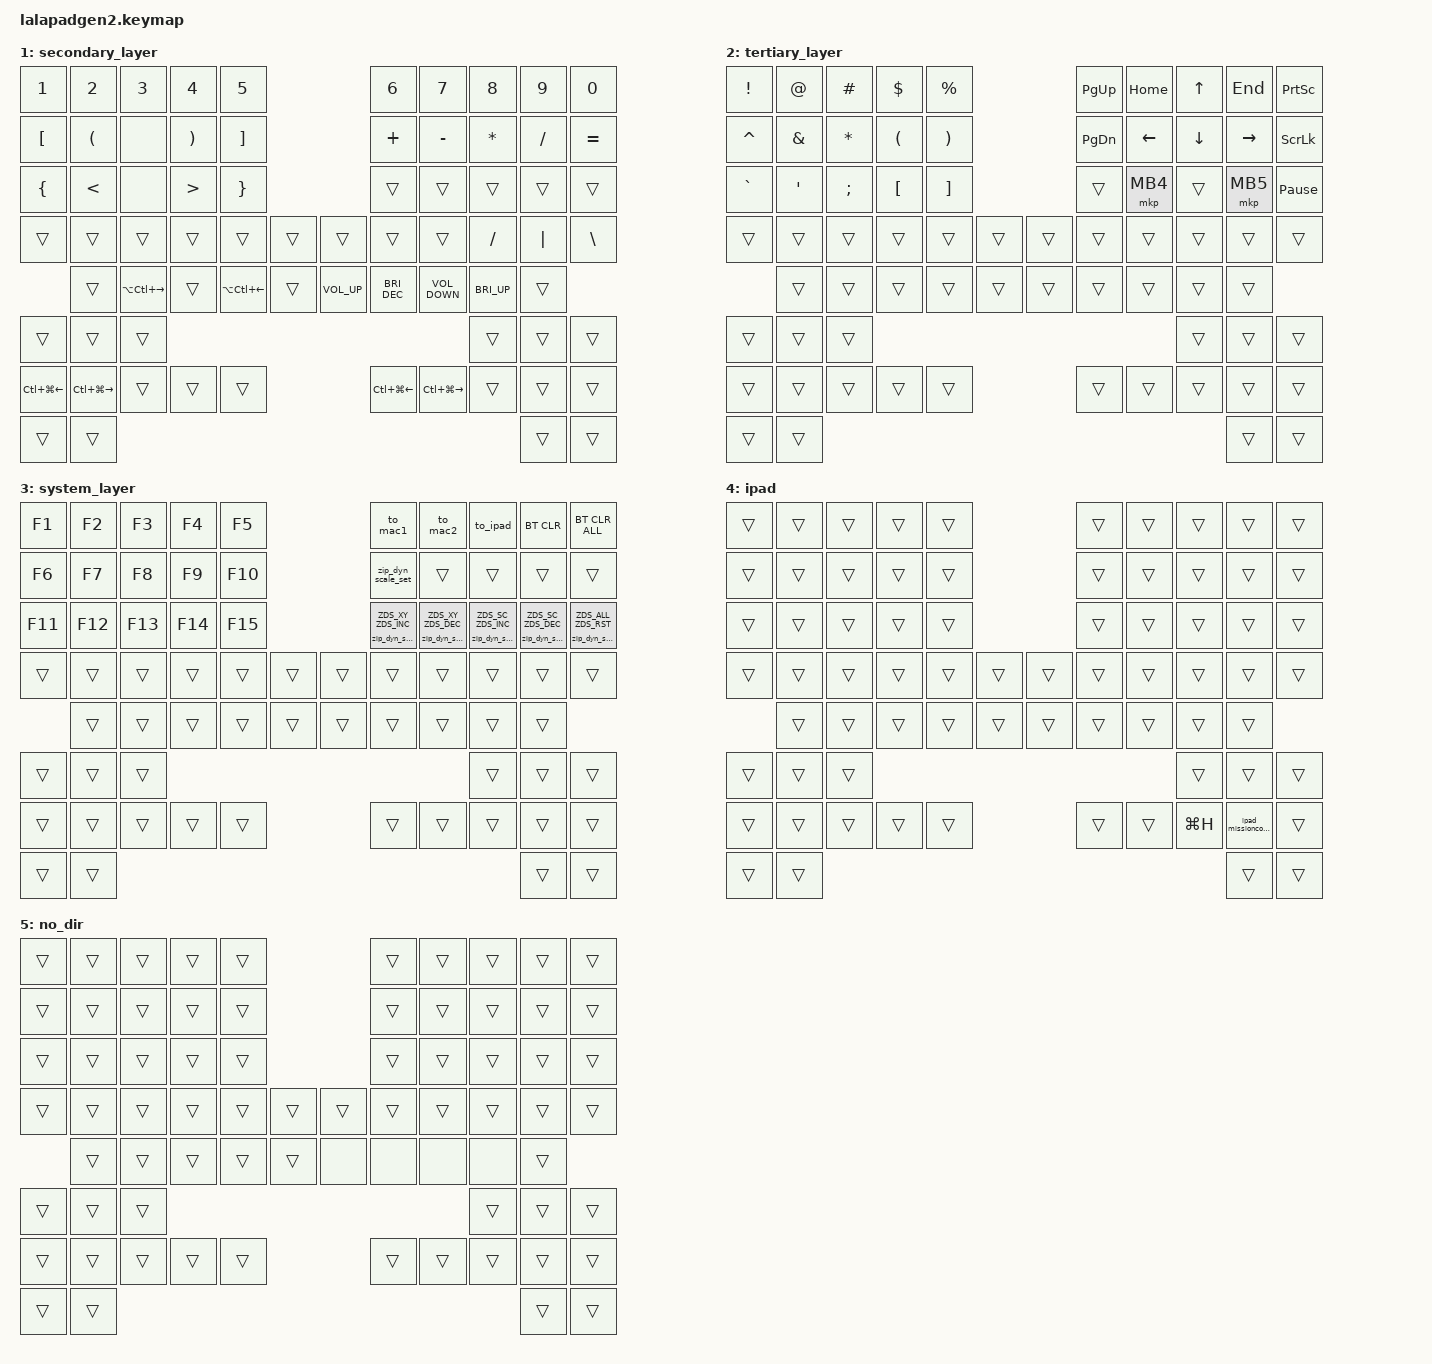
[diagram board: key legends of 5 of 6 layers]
#include <input/processors.dtsi>
#include <dt-bindings/zmk/zip_dynamic_scale.h>
#include <behaviors.dtsi>
#include <dt-bindings/zmk/bt.h>
#include <dt-bindings/zmk/keys.h>
#include <dt-bindings/zmk/pointing.h>

#define DEFAULT_LAYER   0
#define SECONDARY_LAYER 1
#define TERTIARY_LAYER  2
#define SYSTEM_LAYER    3

&mt {
    quick-tap-ms = <250>;
    flavor = "balanced";
};

&lt { quick-tap-ms = <200>; };

/ {
    behaviors {
        dirtap: dirtap {
            compatible = "zmk,behavior-hold-tap";
            label = "DIRTAP";
            #binding-cells = <2>;
            flavor = "tap-unless-interrupted";
            tapping-term-ms = <300>;
            bindings = <&none>, <&kp>;
        };

        zip_dyn_scale: zip_dyn_scale {
            compatible = "zmk,behavior-zip-dynamic-scale";
            #binding-cells = <2>;
        };

        zip_dyn_scale_set: zip_dyn_scale_set {
            compatible = "zmk,behavior-zip-dynamic-scale-set";
            #binding-cells = <2>;
        };

        mt2: mod_tap2 {
            compatible = "zmk,behavior-hold-tap";
            #binding-cells = <2>;
            flavor = "balanced";
            tapping-term-ms = <250>;
            quick-tap-ms = <200>;
            require-prior-idle-ms = <125>;
            bindings = <&kp>, <&kp>;
        };

        tap_dance_layer_1and2: tap_dance_layer_1and2 {
            compatible = "zmk,behavior-tap-dance";
            label = "td_mo12";
            #binding-cells = <0>;
            bindings = <&mo 2>, <&mo 3>;
        };

        mt3: mt3 {
            compatible = "zmk,behavior-hold-tap";
            #binding-cells = <2>;
            flavor = "balanced";
            tapping-term-ms = <250>;
            quick-tap-ms = <200>;
            require-prior-idle-ms = <125>;
            bindings = <&mkp>, <&kp>;

            label = "MT3";
        };

        // 音声入力（VoiceInk）用。タップ=かな／長押し=右⌘（AI なしで録音）／
        // タップしてすぐ押し続ける=右⌥（AI で整えて録音）
        td_voice: td_voice {
            compatible = "zmk,behavior-tap-dance";
            label = "TD_VOICE";
            #binding-cells = <0>;
            tapping-term-ms = <200>;
            bindings = <&mt RIGHT_COMMAND LANGUAGE_1>, <&kp RIGHT_ALT>;
        };

        tap_dance: tap_dance {
            compatible = "zmk,behavior-tap-dance";
            label = "TAP_DANCE";
            #binding-cells = <0>;
            bindings = <&kp T>, <&kp LG(LS(T))>, <&none>;
        };
    };

    combos {
        compatible = "zmk,combos";

        screenshot {
            bindings = <&kp LG(LS(LC(NUMBER_4)))>;
            key-positions = <30 32>;
        };

        screen_capture {
            bindings = <&kp LG(LS(N5))>;
            key-positions = <30 31>;
        };

        task_manager {
            bindings = <&kp LG(LA(ESCAPE))>;
            key-positions = <30 10>;
        };

        lock {
            bindings = <&kp LC(LG(Q))>;
            key-positions = <30 0>;
        };

        escape {
            bindings = <&kp ESCAPE>;
            key-positions = <0 1>;
        };

        copy_pass {
            bindings = <&kp LA(LG(C))>;
            key-positions = <31 32>;
        };
    };

    macros {
        word: word {
            compatible = "zmk,behavior-macro";
            #binding-cells = <0>;
            bindings = <&macro_press &mo 5>, <&macro_tap &kp LANGUAGE_2 &kp LS(T) &kp K &kp Y &kp T &kp M &kp N &kp N5 &kp NUMBER_2 &kp NUMBER_4 &kp N8 &kp ENTER>, <&macro_pause_for_release>, <&macro_release &mo 5>;
            label = "WORD";
        };

        ipad_missioncontroll: ipad_missioncontroll {
            compatible = "zmk,behavior-macro";
            #binding-cells = <0>;
            bindings =
                <&macro_press>,
                <&kp GLOBE>,
                <&macro_tap>,
                <&kp UP>,
                <&macro_release>,
                <&kp GLOBE>;

            label = "IPAD_MISSIONCONTROLL";
        };

        to_mac1: to_mac1 {
            compatible = "zmk,behavior-macro";
            #binding-cells = <0>;
            bindings = <&bt BT_SEL 0 &to 0>;
            label = "TO_MAC1";
        };

        to_mac2: to_mac2 {
            compatible = "zmk,behavior-macro";
            #binding-cells = <0>;
            bindings = <&bt BT_SEL 1 &to 0>;
            label = "TO_MAC2";
        };

        to_ipad: to_ipad {
            compatible = "zmk,behavior-macro";
            #binding-cells = <0>;
            bindings = <&bt BT_SEL 2 &tog 4>;
            label = "TO_IPAD";
        };
    };

    keymap {
        compatible = "zmk,keymap";

        DEFAULT_LAYER {
            display-name = "Default";
            bindings = <
&mt2 SQT Q            &mt2 DOUBLE_QUOTES W  &mt2 GRAVE E          &kp R                         &mt2 TILDE T                                         &kp Y               &kp U            &kp I                 &kp O               &mt2 PERCENT P
&mt2 AT_SIGN A        &mt2 HASH S           &mt2 DOLLAR D         &kp F                         &kp G                                                &mt2 QUESTION H     &kp J            &kp K                 &kp L               &kp MINUS
&kp Z                 &kp X                 &kp C                 &kp V                         &mt2 EXCLAMATION B                                   &mt2 AMPERSAND N    &kp M            &mt2 SEMICOLON COMMA  &mt2 COLON PERIOD   &kp UP_ARROW
&mt LEFT_CONTROL TAB  &mt LEFT_ALT LS(TAB)  &mt LEFT_SHIFT LANG2  &td_voice                     &mt LEFT_COMMAND LANGUAGE_1  &kp SPACE  &lt 1 ENTER  &kp BACKSPACE       &lt 3 BACKSPACE  &kp LEFT              &kp RIGHT           &kp DOWN
                      &none                 &kp RIGHT             &kp DOWN                      &kp LEFT                     &kp UP     &dirtap 0 LC(LA(RET))  &dirtap 0 LC(LA(LEFT_ARROW))  &dirtap 0 LC(LA(BACKSPACE))  &dirtap 0 LC(LA(RIGHT_ARROW))  &word
&none                 &kp LG(LA(V))         &kp LG(LS(V))                                                                                                                                 &mkp LCLK             &mkp RCLK           &mkp MCLK
&kp LC(LEFT_ARROW)    &kp LC(RIGHT)         &kp LG(LA(LC(L)))     &kp LC(UP_ARROW)              &mkp MB5                                             &kp LC(LEFT_ARROW)  &kp LC(RIGHT)    &kp LG(LC(LA(L)))     &kp LC(UP_ARROW)    &mkp MB5
&none                 &none                                                                                                                                                                                     &kp LG(LEFT_ARROW)  &kp LG(RIGHT)
            >;
        };

        SECONDARY_LAYER {
            display-name = "secondary_layer";
            bindings = <
&kp NUMBER_1      &kp NUMBER_2          &kp NUMBER_3       &kp NUMBER_4           &kp N5                                           &kp NUMBER_6      &kp N7             &kp N8        &kp N9     &kp N0
&kp LEFT_BRACKET  &kp LEFT_PARENTHESIS  &none              &kp RIGHT_PARENTHESIS  &kp RIGHT_BRACKET                                &kp PLUS          &kp MINUS          &kp ASTERISK  &kp SLASH  &kp EQUAL
&kp LEFT_BRACE    &kp LESS_THAN         &none              &kp GREATER_THAN       &kp RIGHT_BRACE                                  &trans            &trans             &trans        &trans     &trans
&trans            &trans                &trans             &trans                 &trans                  &trans  &trans           &trans            &trans             &kp SLASH     &kp PIPE   &kp BACKSLASH
                  &trans                &kp LA(LC(RIGHT))  &trans                 &kp LA(LC(LEFT_ARROW))  &trans  &kp C_VOLUME_UP  &kp C_BRI_DEC     &kp C_VOLUME_DOWN  &kp C_BRI_UP  &trans
&trans            &trans                &trans                                                                                                                          &trans        &trans     &trans
&kp LC(LG(LEFT))  &kp LC(LG(RIGHT))     &trans             &trans                 &trans                                           &kp LC(LG(LEFT))  &kp LC(LG(RIGHT))  &trans        &trans     &trans
&trans            &trans                                                                                                                                                              &trans     &trans
            >;
        };

        TERTIARY_LAYER {
            display-name = "tertiary_layer";
            bindings = <
&kp EXCLAMATION  &kp AT_SIGN    &kp HASH      &kp DOLLAR            &kp PERCENT                            &kp PAGE_UP    &kp HOME  &kp UP_ARROW    &kp END    &kp PRINTSCREEN
&kp CARET        &kp AMPERSAND  &kp ASTERISK  &kp LEFT_PARENTHESIS  &kp RIGHT_PARENTHESIS                  &kp PAGE_DOWN  &kp LEFT  &kp DOWN_ARROW  &kp RIGHT  &kp SCROLLLOCK
&kp GRAVE        &kp SQT        &kp SEMI      &kp LEFT_BRACKET      &kp RIGHT_BRACKET                      &trans         &mkp MB4  &trans          &mkp MB5   &kp PAUSE_BREAK
&trans           &trans         &trans        &trans                &trans                 &trans  &trans  &trans         &trans    &trans          &trans     &trans
                 &trans         &trans        &trans                &trans                 &trans  &trans  &trans         &trans    &trans          &trans
&trans           &trans         &trans                                                                                              &trans          &trans     &trans
&trans           &trans         &trans        &trans                &trans                                 &trans         &trans    &trans          &trans     &trans
&trans           &trans                                                                                                                             &trans     &trans
            >;
        };

        SYSTEM_LAYER {
            display-name = "system_layer";
            bindings = <
&kp F1   &kp F2   &kp F3   &kp F4   &kp F5                   &to_mac1                       &to_mac2                       &to_ipad                       &bt BT_CLR                     &bt BT_CLR_ALL
&kp F6   &kp F7   &kp F8   &kp F9   &kp F10                  &zip_dyn_scale_set             &trans                         &trans                         &trans                         &trans
&kp F11  &kp F12  &kp F13  &kp F14  &kp F15                  &zip_dyn_scale ZDS_XY ZDS_INC  &zip_dyn_scale ZDS_XY ZDS_DEC  &zip_dyn_scale ZDS_SC ZDS_INC  &zip_dyn_scale ZDS_SC ZDS_DEC  &zip_dyn_scale ZDS_ALL ZDS_RST
&trans   &trans   &trans   &trans   &trans   &trans  &trans  &trans                         &trans                         &trans                         &trans                         &trans
         &trans   &trans   &trans   &trans   &trans  &trans  &trans                         &trans                         &trans                         &trans
&trans   &trans   &trans                                                                                                   &trans                         &trans                         &trans
&trans   &trans   &trans   &trans   &trans                   &trans                         &trans                         &trans                         &trans                         &trans
&trans   &trans                                                                                                                                           &trans                         &trans
            >;
        };

        iPad {
            display-name = "ipad";
            bindings = <
&trans  &trans  &trans  &trans  &trans                  &trans  &trans  &trans     &trans                 &trans
&trans  &trans  &trans  &trans  &trans                  &trans  &trans  &trans     &trans                 &trans
&trans  &trans  &trans  &trans  &trans                  &trans  &trans  &trans     &trans                 &trans
&trans  &trans  &trans  &trans  &trans  &trans  &trans  &trans  &trans  &trans     &trans                 &trans
        &trans  &trans  &trans  &trans  &trans  &trans  &trans  &trans  &trans     &trans
&trans  &trans  &trans                                                  &trans     &trans                 &trans
&trans  &trans  &trans  &trans  &trans                  &trans  &trans  &kp LG(H)  &ipad_missioncontroll  &trans
&trans  &trans                                                                     &trans                 &trans
            >;
        };

        NO_DIR {
            display-name = "no_dir";
            bindings = <
&trans  &trans  &trans  &trans  &trans  &trans  &trans  &trans  &trans  &trans  &trans  &trans  &trans  &trans  &trans  &trans  &trans  &trans  &trans  &trans  &trans  &trans  &trans  &trans  &trans  &trans  &trans  &trans  &trans  &trans  &trans  &trans  &trans  &trans  &trans  &trans  &trans  &trans  &trans  &trans  &trans  &trans  &trans  &trans  &trans  &trans  &trans  &none  &none  &none  &none  &trans  &trans  &trans  &trans  &trans  &trans  &trans  &trans  &trans  &trans  &trans  &trans  &trans  &trans  &trans  &trans  &trans  &trans  &trans  &trans  &trans
            >;
        };
    };

    conditional_layers { compatible = "zmk,conditional-layers"; };
};
